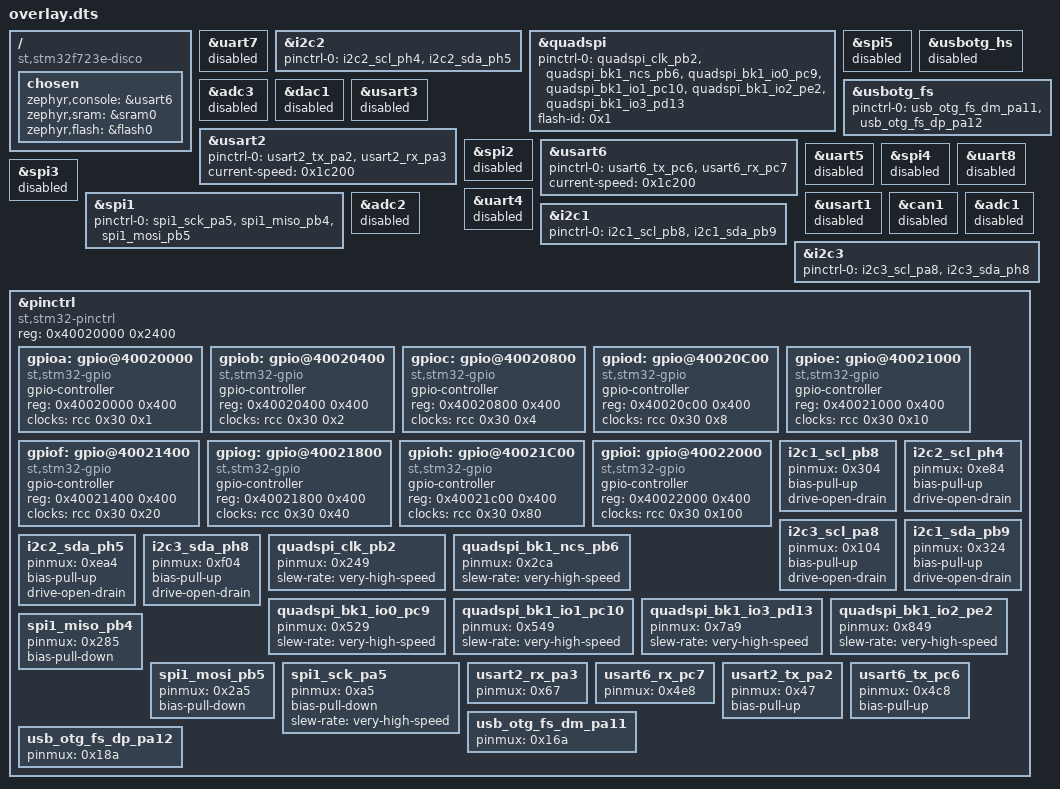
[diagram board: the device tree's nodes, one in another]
/ {
	compatible = "st,stm32f723e-disco";
	chosen {
		zephyr,console = &usart6;
		zephyr,sram = &sram0;
		zephyr,flash = &flash0;
	};
};
&uart7{
	status = "disabled";
};
&i2c2{
	status = "okay";
	pinctrl-0 = < &i2c2_scl_ph4 &i2c2_sda_ph5 >;
	pinctrl-names = "default";
};
&quadspi{
	status = "okay";
	pinctrl-names = "default";
	pinctrl-0 = < &quadspi_clk_pb2 &quadspi_bk1_ncs_pb6 &quadspi_bk1_io0_pc9 &quadspi_bk1_io1_pc10 &quadspi_bk1_io2_pe2 &quadspi_bk1_io3_pd13 >;
	flash-id = < 0x1 >;
};
&spi5{
	status = "disabled";
};
&usbotg_hs{
	status = "disabled";
};
&adc3{
	status = "disabled";
};
&dac1{
	status = "disabled";
};
&usart3{
	status = "disabled";
};
&usart2{
	status = "okay";
	pinctrl-0 = < &usart2_tx_pa2 &usart2_rx_pa3 >;
	pinctrl-names = "default";
	current-speed = < 0x1c200 >;
};
&usbotg_fs{
	status = "okay";
	pinctrl-0 = < &usb_otg_fs_dm_pa11 &usb_otg_fs_dp_pa12 >;
	pinctrl-names = "default";
};
&spi2{
	status = "disabled";
};
&usart6{
	status = "okay";
	pinctrl-0 = < &usart6_tx_pc6 &usart6_rx_pc7 >;
	pinctrl-names = "default";
	current-speed = < 0x1c200 >;
};
&uart5{
	status = "disabled";
};
&spi4{
	status = "disabled";
};
&uart8{
	status = "disabled";
};
&spi3{
	status = "disabled";
};
&spi1{
	status = "okay";
	pinctrl-0 = < &spi1_sck_pa5 &spi1_miso_pb4 &spi1_mosi_pb5 >;
	pinctrl-names = "default";
};
&uart4{
	status = "disabled";
};
&adc2{
	status = "disabled";
};
&usart1{
	status = "disabled";
};
&i2c1{
	status = "okay";
	pinctrl-0 = < &i2c1_scl_pb8 &i2c1_sda_pb9 >;
	pinctrl-names = "default";
};
&can1{
	status = "disabled";
};
&adc1{
	status = "disabled";
};
&i2c3{
	status = "okay";
	pinctrl-0 = < &i2c3_scl_pa8 &i2c3_sda_ph8 >;
	pinctrl-names = "default";
};
&pinctrl{
	compatible = "st,stm32-pinctrl";
	#address-cells = < 0x1 >;
	#size-cells = < 0x1 >;
	reg = < 0x40020000 0x2400 >;
	gpioa: gpio@40020000 {
		compatible = "st,stm32-gpio";
		gpio-controller;
		#gpio-cells = < 0x2 >;
		reg = < 0x40020000 0x400 >;
		clocks = < &rcc 0x30 0x1 >;
	};
	gpiob: gpio@40020400 {
		compatible = "st,stm32-gpio";
		gpio-controller;
		#gpio-cells = < 0x2 >;
		reg = < 0x40020400 0x400 >;
		clocks = < &rcc 0x30 0x2 >;
	};
	gpioc: gpio@40020800 {
		compatible = "st,stm32-gpio";
		gpio-controller;
		#gpio-cells = < 0x2 >;
		reg = < 0x40020800 0x400 >;
		clocks = < &rcc 0x30 0x4 >;
	};
	gpiod: gpio@40020C00 {
		compatible = "st,stm32-gpio";
		gpio-controller;
		#gpio-cells = < 0x2 >;
		reg = < 0x40020c00 0x400 >;
		clocks = < &rcc 0x30 0x8 >;
	};
	gpioe: gpio@40021000 {
		compatible = "st,stm32-gpio";
		gpio-controller;
		#gpio-cells = < 0x2 >;
		reg = < 0x40021000 0x400 >;
		clocks = < &rcc 0x30 0x10 >;
	};
	gpiof: gpio@40021400 {
		compatible = "st,stm32-gpio";
		gpio-controller;
		#gpio-cells = < 0x2 >;
		reg = < 0x40021400 0x400 >;
		clocks = < &rcc 0x30 0x20 >;
	};
	gpiog: gpio@40021800 {
		compatible = "st,stm32-gpio";
		gpio-controller;
		#gpio-cells = < 0x2 >;
		reg = < 0x40021800 0x400 >;
		clocks = < &rcc 0x30 0x40 >;
	};
	gpioh: gpio@40021C00 {
		compatible = "st,stm32-gpio";
		gpio-controller;
		#gpio-cells = < 0x2 >;
		reg = < 0x40021c00 0x400 >;
		clocks = < &rcc 0x30 0x80 >;
	};
	gpioi: gpio@40022000 {
		compatible = "st,stm32-gpio";
		gpio-controller;
		#gpio-cells = < 0x2 >;
		reg = < 0x40022000 0x400 >;
		clocks = < &rcc 0x30 0x100 >;
	};
	i2c1_scl_pb8: i2c1_scl_pb8 {
		pinmux = < 0x304 >;
		bias-pull-up;
		drive-open-drain;
	};
	i2c2_scl_ph4: i2c2_scl_ph4 {
		pinmux = < 0xe84 >;
		bias-pull-up;
		drive-open-drain;
	};
	i2c3_scl_pa8: i2c3_scl_pa8 {
		pinmux = < 0x104 >;
		bias-pull-up;
		drive-open-drain;
	};
	i2c1_sda_pb9: i2c1_sda_pb9 {
		pinmux = < 0x324 >;
		bias-pull-up;
		drive-open-drain;
	};
	i2c2_sda_ph5: i2c2_sda_ph5 {
		pinmux = < 0xea4 >;
		bias-pull-up;
		drive-open-drain;
	};
	i2c3_sda_ph8: i2c3_sda_ph8 {
		pinmux = < 0xf04 >;
		bias-pull-up;
		drive-open-drain;
	};
	quadspi_clk_pb2: quadspi_clk_pb2 {
		pinmux = < 0x249 >;
		slew-rate = "very-high-speed";
	};
	quadspi_bk1_ncs_pb6: quadspi_bk1_ncs_pb6 {
		pinmux = < 0x2ca >;
		slew-rate = "very-high-speed";
	};
	quadspi_bk1_io0_pc9: quadspi_bk1_io0_pc9 {
		pinmux = < 0x529 >;
		slew-rate = "very-high-speed";
	};
	quadspi_bk1_io1_pc10: quadspi_bk1_io1_pc10 {
		pinmux = < 0x549 >;
		slew-rate = "very-high-speed";
	};
	quadspi_bk1_io3_pd13: quadspi_bk1_io3_pd13 {
		pinmux = < 0x7a9 >;
		slew-rate = "very-high-speed";
	};
	quadspi_bk1_io2_pe2: quadspi_bk1_io2_pe2 {
		pinmux = < 0x849 >;
		slew-rate = "very-high-speed";
	};
	spi1_miso_pb4: spi1_miso_pb4 {
		pinmux = < 0x285 >;
		bias-pull-down;
	};
	spi1_mosi_pb5: spi1_mosi_pb5 {
		pinmux = < 0x2a5 >;
		bias-pull-down;
	};
	spi1_sck_pa5: spi1_sck_pa5 {
		pinmux = < 0xa5 >;
		bias-pull-down;
		slew-rate = "very-high-speed";
	};
	usart2_rx_pa3: usart2_rx_pa3 {
		pinmux = < 0x67 >;
	};
	usart6_rx_pc7: usart6_rx_pc7 {
		pinmux = < 0x4e8 >;
	};
	usart2_tx_pa2: usart2_tx_pa2 {
		pinmux = < 0x47 >;
		bias-pull-up;
	};
	usart6_tx_pc6: usart6_tx_pc6 {
		pinmux = < 0x4c8 >;
		bias-pull-up;
	};
	usb_otg_fs_dm_pa11: usb_otg_fs_dm_pa11 {
		pinmux = < 0x16a >;
	};
	usb_otg_fs_dp_pa12: usb_otg_fs_dp_pa12 {
		pinmux = < 0x18a >;
	};
};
